# MAX32570 register map
Vendor: Maxim-Integrated; Series: ARMCM4; File version: 1.0
CPU: CM4 r2p1, little endian, MPU, FPU, 3 interrupt priority bits
Registers are 32-bit, read-write, reset 0x0 unless marked. A register's access mark holds for its fields unless they carry their own. Offsets are from the block's base; [hi:lo] are bit positions; {n}, {i} and the like mark numbered series.

## FLC — Flash Memory Control.
Base 0x40029000; register names take the prefix FLSH_
0x00 ADDR — Flash Write Address.
  [31:0] ADDR — Address for next operation.
0x04 CLKDIV reset 0x64 — Flash Clock Divide. The clock (PLL0) is divided by this value to generate a 1 MHz clock for Flash controller.
  [7:0] CLKDIV — Flash Clock Divide. The clock is divided by this value to generate a 1MHz clock for flash controller.
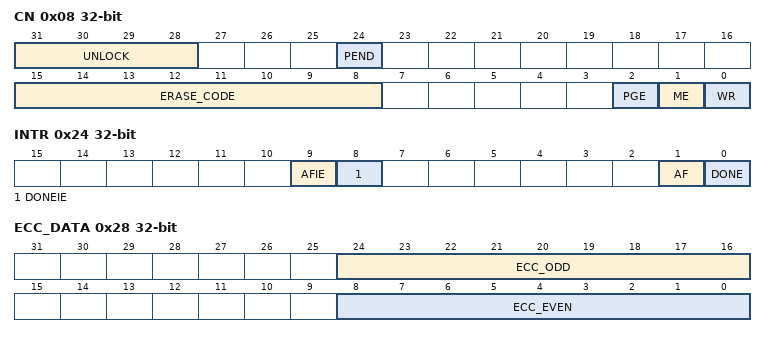
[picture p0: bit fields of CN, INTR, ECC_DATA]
0x08 CN — Flash Control Register.
  [31:28] UNLOCK — Flash Unlock. The correct unlock code must be written to these four bits before any Flash write or erase operation is allowed.
    2=unlocked (Flash Unlocked.); 3=locked (Flash Locked.)
  [24] PEND ro — Flash Pending. When Flash operation is in progress (busy), Flash reads and writes will fail. When PEND is set, write to all Flash registers, with exception of the Flash interrupt register, are ignored.
    0=idle; 1=busy
  [15:8] ERASE_CODE — Erase Code. The ERASE_CODE must be set up property before erase operation can be initiated. These bits are automatically cleared after the operation is complete.
    0=nop (No operation.); 85=erasePage (Enable Page Erase.); 170=eraseAll (Enable Mass Erase. The debug port must be enabled.)
  [2] PGE — Page Erase. This bit is automatically cleared after the operation.
    0=complete (No operation/complete.); 1=Start operation
  [1] ME — Mass Erase. This bit is automatically cleared after the operation.
    0=complete (No operation/complete.); 1=Start operation
  [0] WR — Write. This bit is automatically cleared after the operation.
    0=complete (No operation/complete.); 1=Start operation
0x24 INTR — Flash Interrupt Register.
  [9] AFIE — Flash Done Interrupt Enable.
    0=disable; 1=enable
  [8] DONEIE — Flash Done Interrupt Enable.
    0=disable; 1=enable
  [1] AF — Flash Access Fail. This bit is set when an attempt is made to write the flash while the flash is busy or the flash is locked. This bit can only be set to 1 by hardware.
    0=noError (No Failure.); 1=error (Failure occurs.)
  [0] DONE — Flash Done Interrupt. This bit is set to 1 upon Flash write or erase completion.
    0=inactive (No interrupt is pending.); 1=pending (An interrupt is pending.)
0x28 ECC_DATA
  [24:16] ECC_ODD — Error Correction Code Even Data.
  [8:0] ECC_EVEN — Error Correction Code Odd Data.
{0x30+4i} DATA[{i}] (i=0..3) — Flash Write Data.
  [31:0] DATA — Data next operation.

## HTMR — High Speed Timer Module.
Base 0x4001B000
Same registers: HTMR1 0x4001C000
0x00 SEC reset not defined — HTimer Long-Interval Counter. This register contains the 32 most significant bits of the counter.
  [31:0] RTS — HTimer Long Interval Counter.
0x04 SSEC reset not defined — HTimer Short Interval Counter. This counter ticks every t_htclk (16.48uS). HTIMER_SEC is incremented when this register rolls over from 0xFF to 0x00.
  [7:0] RTSS — HTimer Short Interval Counter.
0x08 RAS reset not defined — Long Interval Alarm.
  [19:0] RAS — HTimer Long Interval Alarm. An Alarm is triggered when this value matches HTIMER_SEC[19:0]
0x0C RSSA reset not defined — HTimer Short Interval Alarm. This register contains the reload value for the short interval alarm, HTIMER_CTRL.alarm_ss_fl is raised on rollover.
  [31:0] RSSA — This register contains the reload value for the short interval alarm.
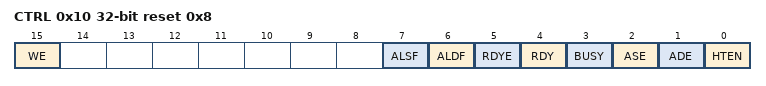
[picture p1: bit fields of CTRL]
0x10 CTRL reset 0x8 (reset mask 0xFFFFFF38) — HTimer Control Register.
  [15] WE — Write Enable. This register bit serves as a protection mechanism against unintentional writes to critical HTimer bits.
    0=dis (Not active.); 1=en
  [7] ALSF ro — Short Interval Alarm Interrupt Flag. This alarm is qualified as wake-up source to the processor.
    0=inactive (Not active.); 1=Pending (Active.)
  [6] ALDF ro — Long Interval Alarm Interrupt Flag. This alarm is qualified as wake-up source to the processor.
    0=inactive (Not active.); 1=pending (Active.)
  [5] RDYE — HTimer Ready Interrupt Enable.
    0=dis (Disable.); 1=en (Enable.)
  [4] RDY — HTimer Ready. This bit is set to 1 by hardware when the HTimer count registers update. It can be cleared to 0 by software at any time. It will also be cleared to 0 by hardware just prior to an update of the HTimer count register.
    0=busy (Register has not updated.); 1=ready
  [3] BUSY ro — HTimer Busy. This bit is set to 1 by hardware when changes to HTimer registers required a synchronized version of the register to be in place. This bit is automatically cleared by hardware.
    0=idle; 1=busy
  [2] ASE — Short Interval Alarm Interrupt Enable. Change to this bit is effective only after BUSY is cleared from 1 to 0.
    0=dis (Disable.); 1=en (Enable.)
  [1] ADE — Long Interval Alarm Interrupt Enable. Change to this bit is effective only after BUSY is cleared from 1 to 0.
    0=dis (Disable.); 1=en (Enable.)
  [0] HTEN — HTimer Enable. This bit enables the Real Time Clock. This bit can only be written when WE=1 and BUSY =0. Change to this bit is effective only after BUSY is cleared from 1 to 0.
    0=dis (Disable.); 1=en (Enable.)
